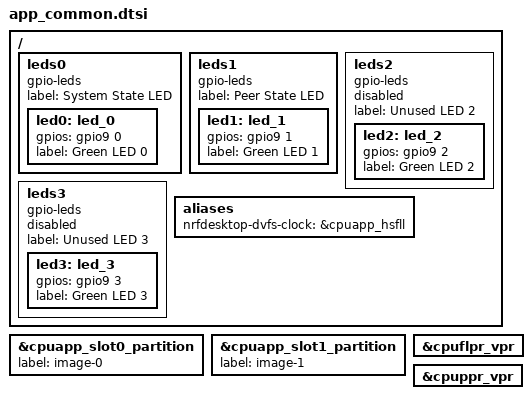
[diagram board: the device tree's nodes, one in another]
/*
 * Copyright (c) 2024-2025 Nordic Semiconductor ASA
 *
 * SPDX-License-Identifier: LicenseRef-Nordic-5-Clause
 */

#include "memory_map.dtsi"

/ {
	/* Redefine leds to fit CAF requirements.
	 * Remove the pwmleds DTS node to prevent the CONFIG_LED_PWM and CONFIG_CAF_LEDS_PWM Kconfig
	 * options from being enabled.
	 */
	/delete-node/ pwmleds;
	/delete-node/ leds;

	leds0 {
		compatible = "gpio-leds";
		status = "okay";
		label = "System State LED";

		led0: led_0 {
			gpios = < &gpio9 0 GPIO_ACTIVE_HIGH >;
			label = "Green LED 0";
		};
	};

	leds1 {
		compatible = "gpio-leds";
		status = "okay";
		label = "Peer State LED";

		led1: led_1 {
			gpios = < &gpio9 1 GPIO_ACTIVE_HIGH >;
			label = "Green LED 1";
		};
	};

	leds2 {
		compatible = "gpio-leds";
		status = "disabled";
		label = "Unused LED 2";

		led2: led_2 {
			gpios = < &gpio9 2 GPIO_ACTIVE_HIGH >;
			label = "Green LED 2";
		};
	};

	leds3 {
		compatible = "gpio-leds";
		status = "disabled";
		label = "Unused LED 3";

		led3: led_3 {
			gpios = < &gpio9 3 GPIO_ACTIVE_HIGH >;
			label = "Green LED 3";
		};
	};

	aliases {
		nrfdesktop-dvfs-clock = &cpuapp_hsfll;

		/delete-property/ pwm-led0;
	};
};

/* Define the necessary aliases for the MCUboot slots that will be used by the DFU transports.
 * Due to the build system limitation, the allowed size of the application image (configured by
 * the code partition DTS node) is incorrectly increased by the size allocated for the radio image.
 */
slot0_partition: &cpuapp_slot0_partition {
	label = "image-0";
};

slot1_partition: &cpuapp_slot1_partition {
	label = "image-1";
};

secondary_app_partition: &cpuapp_slot1_partition {};

/* Remove the undefined property value from the disabled VPR cores to prevent build errors. */
&cpuflpr_vpr {
	/delete-property/ source-memory;
};

&cpuppr_vpr {
	/delete-property/ source-memory;
};
